# dmpac_targetdb register map
Vendor: Texas Instruments
Peripheral module from a debugger description file (folder hts_dmpac).
Registers are 32-bit, read-write, no defined reset value unless marked. A register's access mark holds for its fields unless they carry their own. Offsets are as the file gives them; lines under a group give offsets from that group; [hi:lo] are bit positions; {n}, {i} and the like mark numbered series; 'fields as' and 'values as' point back to an identical list; <NAME> marks a mode.

## DMPAC (part 1 of 5) — Depth and Motion Perception Accelerator (DMPAC)
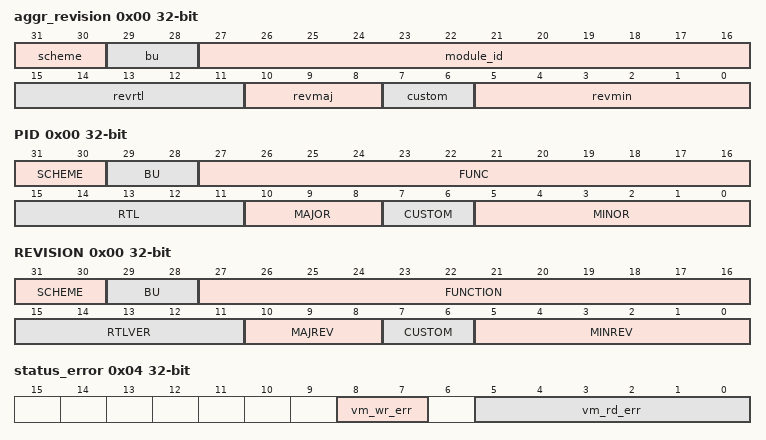
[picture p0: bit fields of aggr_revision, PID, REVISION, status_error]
0x00 aggr_revision ro — Revision parameters
  [31:30] scheme
  [29:28] bu
  [27:16] module_id
  [15:11] revrtl — RTL version
  [10:8] revmaj — Major version
  [7:6] custom — Custom version
  [5:0] revmin — Minor version
0x00 PID ro — DMPAC PID
  [31:30] SCHEME — Used to distinguish between old scheme and new scheme. Spare bit to encode future schemes
  [29:28] BU — BU indicatorDSPS ==> 0x0 WTBU ==> 0x1 Processors ==> 0x2
  [27:16] FUNC — Function indicates a software compatible module family. If there is no level of software compatibility a new FUNC number, and hence PID, should be assigned.
  [15:11] RTL — RTL Version. R as described in PDR with additional clarifications and definitions below. Must be easily ECO-able or controlled during fabrication. Ideally through a top level metal mask or e-fuse. This number is maintained/owned by IP design owner. RTL follows a numbering such as X.Y.R.Z which are explained in this table. R changes ONLY when: (1) PDS uploads occur which may have been due to spec changes (2) Bug fixes occur (3) Resets to '0' when X or Y changes. Design team has an internal 'Z' (customer invisible) number which increments on every drop that happens due to DV and RTL updates. Z resets to 0 when R increments.
  [10:8] MAJOR — Major Revision. X as described in PDR with additional clarifications/definitions below. This number is owned/maintained by IP specification owner. X is part of IP numbering X.Y.R.Z.X changes ONLY when: (1) There is a major feature addition. An example would be adding Master Mode to Utopia Level2. The Func field (or Class/Type in old PID format) will remain the same. X does NOT change due to: (1) Bug fixes (2) Change in feature parameters.
  [7:6] CUSTOM — Indicates a special version for a particular device. Consequence of use may avoid use of standard Chip Support Library (CSL) / Drivers. 0 if non-custom.
  [5:0] MINOR — Minor Revision. Y as described in PDR with additional clarifications/definitions below. This number is owned/maintained by IP specification owner. Y changes ONLY when: (1) Features are scaled (up or down). Flexibility exists in that this feature scalability may either be represented in the Y change or a specific register in the IP that indicates which features are exactly available. (2) When feature creeps from Is-Not list to Is list. But this may not be the case once it sees silicon - in which case X will change. Y does NOT change due to: (1) Bug fixes (2) Typos or clarifications (3) major functional/feature change/addition/deletion. Instead these changes may be reflected via R, S, X as applicable. Spec owner maintains a customer-invisible number 'S' which changes due to: (1) Typos/clarifications (2) Bug documentation. Note that this bug is not due to a spec change but due to implementation. Nevertheless, the spec tracks the IP bugs. An RTL release (say for silicon PG1.1) that occurs due to bug fix should document the corresponding spec number (X.Y.S) in its release notes.
0x00 REVISION ro
  [31:30] SCHEME
  [29:28] BU
  [27:16] FUNCTION — Module ID
  [15:11] RTLVER — RTL revisions
  [10:8] MAJREV — Major revision
  [7:6] CUSTOM — Custom revision
  [5:0] MINREV — Minor revision
{0x0+4i} pipeline_control_{i} (i=0..6) — Enable pipeline to activate all connected scheduler
  [0] pipe_en — Pipeline {i} enable, writing '1' activate pipeline , writing '0' during active pipeline is illegal and behavior is undefined, read '1' -> pipeline is active , read '0' -> pipeline is inactive
0x00 CTSETID ro — CTSET identification register
  [16:12] FUNCTION — Function : Indicates a Debug IP (0x2nn) and 0x80 is the identifier for CT-SET
  [11:5] RTL_VERSION — This field changes on bug fix, and resets to '0' when either Minor Revision or Major Revision field changes
  [8:3] MAJOR_REV — Major Revision. This field changes when there is a major feature change.
  [6:2] CUSTOM — Indicates a special version for a particular device. 0 if non-custom
  [28:2] BU — The value 10b designates this as Processor Business Unit IP
  [30:2] SCHEME — Used to distinguish between old Scheme and current
  [6:0] MINOR_REV — Minor Revision. This field changes when features are scaled up or down
0x00 status_param ro — The STATUS_PARAM register returns the LSE compile configuration parameters.
  [12:5] CORE_DW — Core Input Data Bus Width
  [23:5] CORE_OUT_DW — Core Output Channel Data Width
  [6:4] SL2_OUT_CH — Number of SL2 Output Channels
  [3] SL2_IN_CH_THR — Number of Input Channels per thread
  [17:3] PIX_MX_HT — Core_Input Pixel Matrix Height
  [10:2] SL2_OUT_H3A_CH — Number of SL2 H3A Output Channels
  [30:2] BYPASS_CH — Number of available input channel selection for loopback mode
  [2:1] VPORT_THR — Number of VPORT input enabled
  [20:1] HV_INSERT — H/VBLANK Insertion Supported (if 1)
  [21:1] BIT_AOFFSET — Source nibble offset address Supported (if 1)
  [22:1] LINE_SKIP_EN — Source Line Inc by 2 Supported (if 1)
  [28:1] CORE_OUT_2D — 1D or 2D output addressing mode(2D if 1)
  [29:1] OUT_SKIP_EN — Output Auto-Skip Enable
  [2:0] NTHR — Number of threads supported
0x00 status_param ro — The STATUS_PARAM register returns the LSE compile configuration parameters.
  fields as status_param
0x00 PID ro — DOF PID
  [16:12] FUNC — Function indicates a software compatible module family. If there is no level of software compatibility a new FUNC number, and hence PID, should be assigned.
  [11:5] RTL — RTL Version. R as described in PDR with additional clarifications and definitions below. Must be easily ECO-able or controlled during fabrication. Ideally through a top level metal mask or e-fuse. This number is maintained/owned by IP design owner. RTL follows a numbering such as X.Y.R.Z which are explained in this table. R changes ONLY when: (1) PDS uploads occur which may have been due to spec changes (2) Bug fixes occur (3) Resets to '0' when X or Y changes. Design team has an internal 'Z' (customer invisible) number which increments on every drop that happens due to DV and RTL updates. Z resets to 0 when R increments.
  [8:3] MAJOR — Major Revision. X as described in PDR with additional clarifications/definitions below. This number is owned/maintained by IP specification owner. X is part of IP numbering X.Y.R.Z.X changes ONLY when: (1) There is a major feature addition. An example would be adding Master Mode to Utopia Level2. The Func field (or Class/Type in old PID format) will remain the same. X does NOT change due to: (1) Bug fixes (2) Change in feature parameters.
  [6:2] CUSTOM — Indicates a special version for a particular device. Consequence of use may avoid use of standard Chip Support Library (CSL) / Drivers. 0 if non-custom.
  [28:2] BU — BU indicatorDSPS ==> 0x0 WTBU ==> 0x1 Processors ==> 0x2
  [30:2] SCHEME — Used to distinguish between old scheme and new scheme. Spare bit to encode future schemes
  [6:0] MINOR — Minor Revision. Y as described in PDR with additional clarifications/definitions below. This number is owned/maintained by IP specification owner. Y changes ONLY when: (1) Features are scaled (up or down). Flexibility exists in that this feature scalability may either be represented in the Y change or a specific register in the IP that indicates which features are exactly available. (2) When feature creeps from Is-Not list to Is list. But this may not be the case once it sees silicon - in which case X will change. Y does NOT change due to: (1) Bug fixes (2) Typos or clarifications (3) major functional/feature change/addition/deletion. Instead these changes may be reflected via R, S, X as applicable. Spec owner maintains a customer-invisible number 'S' which changes due to: (1) Typos/clarifications (2) Bug documentation. Note that this bug is not due to a spec change but due to implementation. Nevertheless, the spec tracks the IP bugs. An RTL release (say for silicon PG1.1) that occurs due to bug fix should document the corresponding spec number (X.Y.S) in its release notes.
0x00 PSE_MEM_RAM ro — pse_mem_ram diagnostic read only port, vbusp will stall until RAM is available for read
  [32:0] data — Data read from RAM. RAM is wider than 32bit vbus. MMR reads are byte addresses into RAM where RAM Width is extended/zero padded to next pwr2.
0x00 PID ro — SDE PID
  [16:12] FUNC — Function indicates a software compatible module family. If there is no level of software compatibility a new FUNC number, and hence PID, should be assigned.
  [11:5] RTL — RTL Version. R as described in PDR with additional clarifications and definitions below. Must be easily ECO-able or controlled during fabrication. Ideally through a top level metal mask or e-fuse. This number is maintained/owned by IP design owner. RTL follows a numbering such as X.Y.R.Z which are explained in this table. R changes ONLY when: (1) PDS uploads occur which may have been due to spec changes (2) Bug fixes occur (3) Resets to '0' when X or Y changes. Design team has an internal 'Z' (customer invisible) number which increments on every drop that happens due to DV and RTL updates. Z resets to 0 when R increments.
  [8:3] MAJOR — Major Revision. X as described in PDR with additional clarifications/definitions below. This number is owned/maintained by IP specification owner. X is part of IP numbering X.Y.R.Z.X changes ONLY when: (1) There is a major feature addition. An example would be adding Master Mode to Utopia Level2. The Func field (or Class/Type in old PID format) will remain the same. X does NOT change due to: (1) Bug fixes (2) Change in feature parameters.
  [6:2] CUSTOM — Indicates a special version for a particular device. Consequence of use may avoid use of standard Chip Support Library (CSL) / Drivers. 0 if non-custom.
  [28:2] BU — BU indicatorDSPS ==> 0x0 WTBU ==> 0x1 Processors ==> 0x2
  [30:2] SCHEME — Used to distinguish between old scheme and new scheme. Spare bit to encode future schemes
  [6:0] MINOR — Minor Revision. Y as described in PDR with additional clarifications/definitions below. This number is owned/maintained by IP specification owner. Y changes ONLY when: (1) Features are scaled (up or down). Flexibility exists in that this feature scalability may either be represented in the Y change or a specific register in the IP that indicates which features are exactly available. (2) When feature creeps from Is-Not list to Is list. But this may not be the case once it sees silicon - in which case X will change. Y does NOT change due to: (1) Bug fixes (2) Typos or clarifications (3) major functional/feature change/addition/deletion. Instead these changes may be reflected via R, S, X as applicable. Spec owner maintains a customer-invisible number 'S' which changes due to: (1) Typos/clarifications (2) Bug documentation. Note that this bug is not due to a spec change but due to implementation. Nevertheless, the spec tracks the IP bugs. An RTL release (say for silicon PG1.1) that occurs due to bug fix should document the corresponding spec number (X.Y.S) in its release notes.
0x00 CS_HIST_RAM ro — cs_hist_ram diagnostic read only port, vbusp will stall until RAM is available for read
  [21:11] rsvd — Always read as 0. Writes have no effect.
  [21:0] data — Data read from RAM
0x00 dru_pid ro — Peripheral ID Register
  [32:0] revision — PID Revision
0x00 dru_shared_evt_set access per field — DRU Shared Event Set Register
  [1:0] prot_err wo — Set the Prot Error event
0x00 cfg access per field — Configuration Register for Queue 0
  [16:8] consecutive_trans rw — This is the number of consecutive transactions that will be sent before allowing another queue of equal level to arbitrate to send commands. This is the maximum number of commands that it can send. If the queue has any delays such as virtual address lookup then the arbitration will be forced regardless of the number of commands.
  [24:8] rearb_wait rw — This is the number of commands that will be sent by other queues before allowing the queue to arbitrate again for the right to send commands. This is only started when a queue exhausted its consecutive trans count.
  [4] orderid rw — This configures the orderid for QUEUE0.
  [8:3] qos rw — This configures the QOS for QUEUE0. This should only be set for fixed priority queues and the lower queue should have the lower QoS.
  [3:0] pri rw — This configures the priority for QUEUE0. This will be the priority that will be presented on the External bus for all commands from this queue.
0x00 pid ro — The Revision Register contains the major and minor revisions for the module.
  [16:12] func — Module ID
  [11:5] rtl — RTL revision. Will vary depending on release.
  [8:3] major — Major revision
  [6:2] custom
  [28:2] bu — Business Unit: 10 = Processors
  [30:2] scheme — PID register scheme
  [6:0] minor — Minor revision
0x00 ecc_aggr_cfg_fw_region_0_control — The FW Region 0 Control Register defines the control fields for the slave ksdw_ecc_aggr.cfg region 0 firewall.
  [4:1] lock — Lock region. Once set region values cannot be modified.
  [8:1] background — Background enable for region. There can be 1 backgroun region per FW and foreground regions can have overlapping addresses only with the background region.
  [9:1] cache_mode — Cache mode for region. Set to 1 to check cache permissions. Set to 0 to ignore cache permissions.
  [4:0] enable — Enable region. A value of 0xA enables, others disable.
0x00 pid ro — The Revision Register contains the major and minor revisions for the module.
  fields as pid
{0x0+0x400*i} msram{i}_fw_region_0_control (i=0..3) — The FW Region 0 Control Register defines the control fields for the slave ksbus_msram{i}.slv region 0 firewall.
  fields as ecc_aggr_cfg_fw_region_0_control
0x04 status_error — The STATUS_ERROR register returns the LSE error status.
  [8:7] vm_wr_err — VBUSM I/F Last Write Error Status [14:11] Write Channel Number [10:8] VBUSM write error status
  [5:0] vm_rd_err — VBUSM I/F Last Read Error Status [4:3] Read Channel Number [2:0] VBUSM read error status
0x04 status_error — The STATUS_ERROR register returns the LSE error status.
  fields as status_error
0x04 dofcr access per field — Controls DOF operations
  [1] pyc_en_cfg rw — Pyramidal Top Co-located Predictor Enable bit. Set to 0x1 to enable use of pyramidal top colocated predictor during DOF processing.
  [2:1] pyl_en_cfg rw — Pyramidal Top Left Predictor Enable bit. Set to 0x1 to enable use of pyramidal top left predictor during DOF processing.
  [3:1] tp_en_cfg rw — Temporal Predictor Enable bit. Set to 0x1 to enable use of temporal predictor during the DOF processing.
  [4:1] dl_en_cfg rw — Delayed Left Predictor Enable bit. Set to 0x1 to enable use of delayed left predictor during the DOF processing.
  [16:1] lk_cs_en_cfg rw — LK refinement and confidence score generation enable bit. Set to 0x1 to enable LK and CS processing.
  [17:1] mf_en_cfg rw — Median filter enable bit. Set to 0x1 to enable median filter processing.
  [18:1] sofsparseen_cfg rw — sparse optical flow enable bit. Set to 0x1 to enable sparse optical flow processing.
  [24:1] cur_ct_type_cfg rw — Census transform type for current image.0: 24 bits generated for census transform by using a 5x5 neighborhood around the pixel.1: 32 bits generated for census transform by using a 7x7 neighborhood around the pixel where only 8 pixels are used from the periphery.
  [25:1] ref_ct_type_cfg rw — Census transform type for reference image.0: 24 bits generated for census transform by using a 5x5 neighborhood around the pixel.1: 32 bits generated for census transform by using a 7x7 neighborhood around the pixel where only 8 pixels are used from the periphery.
  [1:0] dof_en_cfg rw — DOF Enable. Set to 0x1 to enable DOF engine.
0x04 CTRL_REG access per field — SDE control register contains fields that can be used to control DMPAC operation.
  [28:4] rsvd ro — always read as 0. Write has no effect
  [1] sdeen rw — SDE enable. Write a '1' to enable DMPAC stereo
  [2:1] medfen rw — Median filter enable. Write a '1' to enable median filter for post processing
  [3:1] rrsrchen rw — Enable reduced range search on pixels near right margin where the search range is less than the configured maximum disparity. Write a '1' to enable reduced range search. Default is full range search where disparity is only produced for pixels where a full range search is possible
  [1:0] rsvd1 ro — always read as 0. Write has no effect
0x04 destination_id — The Destination ID Register defines the destination ID value for error messages.
  [8:0] dest_id — The destination ID.
{0x4+4i} ecc_aggr_cfg_fw_region_0_permission_{i} (i=0..2) — The FW Region 0 Permission {i} Register defines the permissions for the slave ksdw_ecc_aggr.cfg region 0 firewall.
  [16:8] priv_id — Allowed privid.
  [1] sec_supv_read — Secure supervisor read allowed.
  [2:1] sec_supv_cacheable — Secure supervisor cacheable allowed.
  [3:1] sec_supv_debug — Secure supervisor debug allowed.
  [4:1] sec_user_write — Secure user write allowed.
  [5:1] sec_user_read — Secure user read allowed.
  [6:1] sec_user_cacheable — Secure user cacheable allowed.
  [7:1] sec_user_debug — Secure user debug allowed.
  [8:1] nonsec_supv_write — Non-secure supervisor write allowed.
  [9:1] nonsec_supv_read — Non-secure supervisor read allowed.
  [10:1] nonsec_supv_cacheable — Non-secure supervisor cacheable allowed.
  [11:1] nonsec_supv_debug — Non-secure supervisor debug allowed.
  [12:1] nonsec_user_write — Non-secure user write allowed.
  [13:1] nonsec_user_read — Non-secure user read allowed.
  [14:1] nonsec_user_cacheable — Non-secure user cacheable allowed.
  [15:1] nonsec_user_debug — Non-secure user debug allowed.
  [1:0] sec_supv_write — Secure supervisor write allowed.
0x04 destination_id — The Destination ID Register defines the destination ID value for error messages.
  [8:0] dest_id — The destination ID.
{0x4+0x400*i} msram{i}_fw_region_0_permission_0 (i=0..3) — The FW Region 0 Permission 0 Register defines the permissions for the slave ksbus_msram{i}.slv region 0 firewall.
  fields as ecc_aggr_cfg_fw_region_0_permission_0
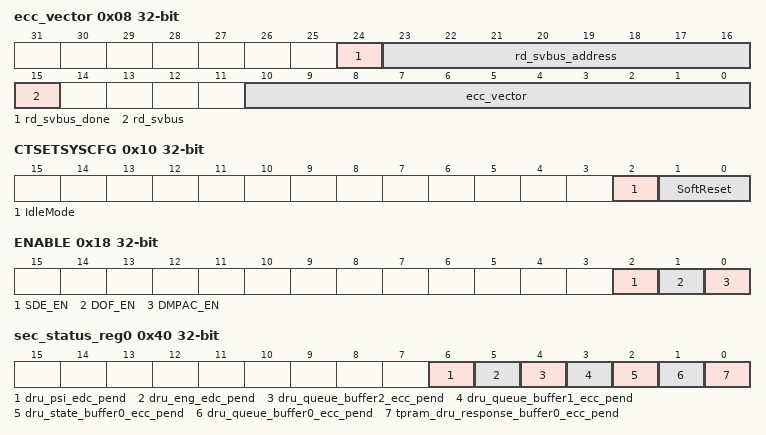
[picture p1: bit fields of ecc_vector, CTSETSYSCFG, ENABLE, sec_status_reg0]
0x08 ecc_vector
  [24] rd_svbus_done — Status to indicate if read on serial VBUS is complete, write of any value will clear this bit.
  [23:16] rd_svbus_address — Read address
  [15] rd_svbus — Write 1 to trigger a read on the serial VBUS
  [10:0] ecc_vector — Value written to select the corresponding ECC RAM for control or status
0x08 status_idle_mode ro — The STATUS_IDLE_MODE register returns IDLE status of LSE VBUSM port and in/output channels - 0: IDLE 1: ACTIVE
  [4] lse_in_chan — Input Channel[3:0] Status
  [12:4] lse_out_chan — Output Channel[3:0] Status
  [1] vm_wr_port — SL2 vbusm I/F Write Port Status
  [1:0] vm_rd_port — SL2 vbusm I/F Read Port Status
0x08 status_idle_mode ro — The STATUS_IDLE_MODE register returns IDLE status of LSE VBUSM port and in/output channels - 0: IDLE 1: ACTIVE
  fields as status_idle_mode
0x08 dofstat ro — Provides status info
  [10] curpaxaddrx_sts — Current Paxel Address X co-ordinate. Provides address of 2x2 paxel currently being processed.
  [9:1] curpaxaddry_sts — Current Paxel Address Y co-ordinate. Provides address of 2x2 paxel currently being processed.
  [1:0] dofact_sts — DOF Active Status. When read as 0x1, indicates DOF engine is in active state processing flow vector for the frame.
0x08 STATUS_REG ro — SDE status register contains fields that return the DMPAC stereo internal status.
  [21:11] rsvd — always read as 0. Write has no effect
  [2] medfcgstat — Median filter sub-module status: 2'b00: IDLE, 2'b01: ACTIVE, 2'b10: PAUSE, 2'b11: RSVD
  [4:2] drcgstat — DRCG sub-module status: 2'b00: IDLE, 2'b01: ACTIVE, 2'b10: PAUSE, 2'b11: RSVD
  [6:2] scastat — SCA sub-module status: 2'b00: IDLE, 2'b01: ACTIVE, 2'b10: PAUSE, 2'b11: RSVD
  [8:2] lccstat — LCC sub-module status: 2'b00: IDLE, 2'b01: ACTIVE, 2'b10: PAUSE, 2'b11: RSVD
  [10:1] sdeidle — sdeidle=1 indicate SDE is idle
  [2:0] dpackstat — Disparity packing sub-module status: 2'b00: IDLE, 2'b01: ACTIVE, 2'b10: PAUSE, 2'b11: RSVD
0x08 dru_capabilities ro — DRU Capabilities: Lists the capabilities of the channel for TR TYPE and formatting functions
  [20:12] rsvd_conf_spec — Reserved for Configuration Specific Features. This implementation has no configuration specific features.
  [35:4] eltype — Maximum element type value that is supported
  [39:4] dfmt — Maximum data reformatting function that is supported
  [43:4] sectr — Maximum second TR function that is supported
  [32:3] amode — The maximum AMODE that is supported. If AMODE is supported then DIR field must be supported for that AMODE.
  [1] type1 — Type 1 TR is supported
  [n:1] type{n} (n=2..15) — Type {n} TR is supported
  [16:1] trstatic — STATIC Field is supported
  [17:1] eol — EOL Field is supported
  [18:1] local_trig — Dedicated Local Trigger is supported
  [19:1] global_trig — Global Triggers 0 and 1 are supported
  [1:0] type0 — Type 0 TR is supported
{0x8+0x400*i} msram{i}_fw_region_0_permission_1 (i=0..3) — The FW Region 0 Permission 1 Register defines the permissions for the slave ksbus_msram{i}.slv region 0 firewall.
  fields as ecc_aggr_cfg_fw_region_0_permission_0
0x0C misc_status ro
  [10:0] num_rams — Indicates the number of RAMS serviced by the ECC aggregator
0x0C cfg_lse — The CFG_LSE register configures the LSE general hardware modes.
  [4:1] vm_arb_fixed_mode — VBUSM Arbitration Fixed Mode select 0: Round-Robin Arbitration (default) 1: Fixed-mode Arbitration
  [8:1] psa_en — Test mode Output Channel Signature Generation Enable 0: Disable (default) 1: EnableWhen enabled, LSE generates a unique CRC signature for each output channel's frame data at frame completion.
0x0C cfg_lse — The CFG_LSE register configures the LSE general hardware modes.
  fields as cfg_lse
0x0C IMGRES_REG access per field — SDE image resolution register contains fields that can be used to configure input image resolution.
  [23:9] rsvd ro — always read as 0. Write has no effect
  [16:7] iwinc rw — Image width increment factor. Image width iw=128 + 16*iwinc pixels, iwinc=0,1,...,120. Any value greater than 120 will be treated as 120.
  [10:6] rsvd1 ro — always read as 0. Write has no effect
  [6:0] ihinc rw — Image height increment factor. Image height ih=64 + 16*ihinc pixels, ihinc=0,1,...,60. Any value greater than 60 will be treated as 60.
{0xC+0x400*i} msram{i}_fw_region_0_permission_2 (i=0..3) — The FW Region 0 Permission 2 Register defines the permissions for the slave ksbus_msram{i}.slv region 0 firewall.
  fields as ecc_aggr_cfg_fw_region_0_permission_0
0x10 reserved_svbus — Reference other documents that contain the ECC RAM wrapper and EDC controller serial vbus register sets.
  [31:0] data — Serial VBUS register data
0x10 eoi_reg — End of Interrupt Register
  [7:0] eoi_vector — End of Interrupt Vector
0x10 CTSETSYSCFG access per field — CTSET system configuration register
  [2] IdleMode rw — Sets the Idle Mode for CTSET (0=Force Idle, 1=No Idle, 2=Smart Idle, 3= Smart Idle wakeup)
  [1:0] SoftReset rw — This will reset entire CTSET, except the registers and the CFG interface. This bit is automatically cleared by hardware. Reads always return 0
0x10 dofres access per field — Set up frame width, height
  [16:11] height_cfg rw — Height of frame (in pixel) to be processed by Optical Flow engine. 1024 pixel max and 16 pixels min. Refer to algorithm parameter section for restrictions.
  [12:0] width_cfg rw — Width of frame (in pixel) to be processed by Optical Flow engine. 2048 pixel max and 32 pixels min. Refer to algorithm parameter section for restrictions.
0x10 SRCHRNG_REG access per field — SDE search range register contains fields that can be used to configure disparity search range.
  [29:3] rsvd ro — always read as 0. Write has no effect
  [2:1] cfgdrange rw — Configure disparity search range in pixels. 2'b00: search range= 64 (-3 to 60 or 0 to 63), 2'b01:search range=128 (-3 to 124 or 0 to 127), others: search range =192 (-3 to 188 or 0 to 191).
  [1:0] cfgdmin rw — Configure minimum disparity (minDisp) to be searched in pixels. 0: minDisp=0, 1:minDisp= -3.
0x10 ecc_aggr_cfg_fw_region_0_start_address_l access per field — The FW Region 0 Start Address Low Register defines the start address bits 31 to 0 for the slave ksdw_ecc_aggr.cfg region 0 firewall.
  [20:12] start_address_l rw — Start address bits 31 to 12. Lowest 12 bits are forced to 0 as address must be 4KB aligned.
  [12:0] start_address_lsb ro — Start address bits 11 to 0 are forced to 0 as address must be 4KB aligned.
{0x10+0x400*i} msram{i}_fw_region_0_start_address_l access per field (i=0..3) — The FW Region 0 Start Address Low Register defines the start address bits 31 to 0 for the slave ksbus_msram{i}.slv region 0 firewall.
  fields as ecc_aggr_cfg_fw_region_0_start_address_l
0x14 intr_vector_reg ro — Interrupt Vector Register
  [31:0] intr_vector
0x14 SETSTR ro — CTSET status register
  [8:1] HWFIFOEmpty — System Event Trace FIFO status, 1 is empty, 0 means captured data not yet exported
  [1:0] ResetDone — Reset status, 0 means reset ongoing, 1 indicates completed
0x14 dofsr access per field — Setup horizontal and vertical search range.
  [16:6] vsr_p_cfg rw — Positive or Downward direction Vertical Search Range in pixels.
  [24:6] vsr_n_cfg rw — Negative or Upward direction Vertical Search Range in pixels.
  [8:0] hsr_cfg rw — Horizontal Search Range in pixels in both the directions.
0x14 LRCHCK_REG access per field — SDE left-right consistence check register contains fields that can be used to configure left-right consistence check.
  [24:8] rsvd ro — always read as 0. Write has no effect
  [8:0] diffthld rw — Left-right consistence check threshold in pixels. Program diffThld >= maxDisp-minDisp will disable Left-right consistence check.
0x14 ecc_aggr_cfg_fw_region_0_start_address_h — The FW Region 0 Start Address High Register defines the start address bits 47 to 32 for the slave ksdw_ecc_aggr.cfg region 0 firewall.
  [16:0] start_address_h — Start address bits 47 to 32.
{0x14+0x400*i} msram{i}_fw_region_0_start_address_h (i=0..3) — The FW Region 0 Start Address High Register defines the start address bits 47 to 32 for the slave ksbus_msram{i}.slv region 0 firewall.
  [16:0] start_address_h — Start address bits 47 to 32.
0x18 ENABLE access per field — DMPAC Enable
  [2] SDE_EN rw — Stereo Enable
  [1] DOF_EN rw — Optical Flow Enable
  [0] DMPAC_EN rw — DMPAC Enable
0x18 DBGTIMELOW ro — The 32 low order bits of the debug time value supplied on the time input interface
  [32:0] DBGTIME — debug time
0x18 sof access per field — Controls sparse optical flow output processing
  [12:0] max_output_count_per_line_cfg rw — Maximum number of MV output per line in case of sparse optical flow processing
0x18 TXTFLT_REG access per field — SDE texture based filtering control register contains fields that can be used to configure texture based filtering function.
  [23:9] rsvd ro — always read as 0. Write has no effect
  [8:1] txtthld rw — Scaled texture threshold. Any pixel whose texture metric is lower than txtthld is considered to be low texture. It is specified as normalized texture threshold times 1024. For instance, if txtthld = 204, the normalized texture threshold is 204/1024 = 0.1992.
  [1:0] txtflten rw — Enable texture based filtering
0x18 ecc_aggr_cfg_fw_region_0_end_address_l access per field — The FW Region 0 End Address Low Register defines the end address bits 31 to 0 to include for the slave ksdw_ecc_aggr.cfg region 0 firewall.
  [20:12] end_address_l rw — End address bits 31 to 12 to include in the match. Lowest 12 bits are forced to 1s as address must be 4KB aligned.
  [12:0] end_address_lsb ro — End address bits 11 to 0 are forced to 1s as address must be 4KB aligned minus 1.
{0x18+0x400*i} msram{i}_fw_region_0_end_address_l access per field (i=0..3) — The FW Region 0 End Address Low Register defines the end address bits 31 to 0 to include for the slave ksbus_msram{i}.slv region 0 firewall.
  fields as ecc_aggr_cfg_fw_region_0_end_address_l
0x1C CG_ENABLE_OVERRIDE access per field — Register to override the root clock gating done in DMPAC to reduce power.By default these bits are 0. it should be set to 1 only when we encounter some silicon bug.
  [0] cg_override rw — clock gating override
0x1C DBGTIMEHI ro — The 32 high order bits of the debug time value supplied on the time input interface
  [32:0] DBGTIME — debug time
0x1C PNLTY_REG access per field — SDE cost penalty configuration register contains fields that can be used to configure cost penalty function.
  [23:9] rsvd ro — always read as 0. Write has no effect
  [8:7] rsvd1 ro — always read as 0. Write has no effect
  [16:7] p1 rw — SDE aggregation penalty P1. Optimization penalty constant for small disparity change.
  [8:0] p2 rw — SDE aggregation penalty P2. Optimization penalty constant for large disparity change. p2 LTEQ 192. Any value greater than 192 will be treated as 192
0x1C ecc_aggr_cfg_fw_region_0_end_address_h — The FW Region 0 End Address High Register defines the end address bits 47 to 32 to include for the slave ksdw_ecc_aggr.cfg region 0 firewall.
  [16:0] end_address_h — End address bits 47 to 32 to include in the match.
{0x1C+0x400*i} msram{i}_fw_region_0_end_address_h (i=0..3) — The FW Region 0 End Address High Register defines the end address bits 47 to 32 to include for the slave ksbus_msram{i}.slv region 0 firewall.
  fields as ecc_aggr_cfg_fw_region_0_end_address_h
0x20 cfgwbase access per field — Current Frame GW Base address in SL2
  [20:0] addr_cfg rw — SL2 base byte address. Should be aligned to 64 bytes
0x20 CONFMAPG0_REG access per field — SDE confidence score mapping configuration register 0 specifies level 0 and 1 mapping threshold.
  [23:9] rsvd0 ro — always read as 0. Write has no effect
  [9:7] rsvd1 ro — always read as 0. Write has no effect
  [16:7] confmap_0 rw — SDE confidence score mapping 0. Internal confidence score will map to level 0 (of 8 level output) if it is less than confmap_0
  [7:0] confmap_1 rw — SDE confidence score mapping 1. Internal confidence score will map to level 1 if it is less than confmap_1 but greater than or equal to confmap_0
0x20 exception_logging_control — The Exception Logging Control Register controls the exception logging.
  [1] disable_pend — Disables logging pending when set.
  [1:0] disable_f — Disables logging when set.
0x20 exception_logging_control — The Exception Logging Control Register controls the exception logging.
  fields as exception_logging_control
{0x20+0x400*i} msram{i}_fw_region_1_control (i=0..3) — The FW Region 1 Control Register defines the control fields for the slave ksbus_msram{i}.slv region 1 firewall.
  fields as ecc_aggr_cfg_fw_region_0_control
0x24 CTSETCFG access per field — The 32 low order bits of the debug time value supplied on the time input interface The 32 high order bits of the debug time value supplied on the time input interface. Reading DBGTIMEHI latches the lower 32 bits of debug time value CTSET configuration register
  [28:4] Claim rw — Claim control and status. To program any bits other than 31 : 28, CTSET ownership must be claimed using bits 31 : 28.
  [1] StartCapt rw — Start capturing system events from external trigger detection
  [2:1] StopCapt rw — Stop capturing system events from external trigger detection
  [3:1] MsgMode rw — Message generated based on event detection, 0 is sampling window, 1 is event detection
  [4:1] EventLevel rw — 0 enables low level event detection, 1 enables high level event detection
  [7:1] SysEventCaptEn rw — When 1 the System event capture is enabled
0x24 cfgwwidth access per field — CFGW width, Max 2048 pix
  [13:0] width_cfg rw — Width of Frame Growing Window in bytes. Should be multiple of 64 bytes
0x24 CONFMAPG1_REG access per field — SDE confidence score mapping configuration register 1 specifies level 2 and 3 mapping threshold.
  [23:9] rsvd0 ro — always read as 0. Write has no effect
  [9:7] rsvd1 ro — always read as 0. Write has no effect
  [16:7] confmap_2 rw — SDE confidence score mapping 2. Internal confidence score will map to level 2 if it is less than confmap_2 but greater than or equal to confmap_1
  [7:0] confmap_3 rw — SDE confidence score mapping 3. Internal confidence score will map to level 3 if it is less than confmap_3 but greater than or equal to confmap_2
0x24 exception_logging_header0 ro — The Exception Logging Header 0 Register contains the first word of the header.
  [16:8] src_id — Source ID.
  [24:8] type_f — Type.
  [8:0] dest_id — Destination ID.
0x24 exception_logging_header0 ro — The Exception Logging Header 0 Register contains the first word of the header.
  fields as exception_logging_header0
{0x24+0x400*i} msram{i}_fw_region_1_permission_0 (i=0..3) — The FW Region 1 Permission 0 Register defines the permissions for the slave ksbus_msram{i}.slv region 1 firewall.
  fields as ecc_aggr_cfg_fw_region_0_permission_0
0x28 SETSPLREG access per field — System Event Sampling Window register
  [8:0] WindowSize rw — System events sampling window size expressed as CTSET cycles
0x28 cfgwheight access per field — CFGW Height, Max 32 rows
  [5:0] height_cfg rw — Height of Frame Growing Window. Max 31 rows.
0x28 CONFMAPG2_REG access per field — SDE confidence score mapping configuration register 2 specifies level 4 and 5 mapping threshold.
  [23:9] rsvd0 ro — always read as 0. Write has no effect
  [9:7] rsvd1 ro — always read as 0. Write has no effect
  [16:7] confmap_4 rw — SDE confidence score mapping 4. Internal confidence score will map to level 4 if it is less than confmap_4 but greater than or equal to confmap_3
  [7:0] confmap_5 rw — SDE confidence score mapping 5. Internal confidence score will map to level 5 if it is less than confmap_5 but greater than or equal to confmap_4
0x28 exception_logging_header1 ro — The Exception Logging Header 1 Register contains the second word of the header.
  [16:8] code, [24:8] group
0x28 exception_logging_header1 ro — The Exception Logging Header 1 Register contains the second word of the header.
  [16:8] code, [24:8] group
{0x28+0x400*i} msram{i}_fw_region_1_permission_1 (i=0..3) — The FW Region 1 Permission 1 Register defines the permissions for the slave ksbus_msram{i}.slv region 1 firewall.
  fields as ecc_aggr_cfg_fw_region_0_permission_0
0x2C CONFMAPG3_REG access per field — SDE confidence score mapping configuration register 3 specifies level 6 and 7 mapping threshold.
  [23:9] rsvd0 ro — always read as 0. Write has no effect
  [16:7] confmap_6 rw — SDE confidence score mapping 6. Internal confidence score will map to level 6 if it is less than confmap_6 but greater than or equal to confmap_5
  [16:0] rsvd1 ro — always read as 0. Write has no effect
0x2C exception_logging_data0 ro — The Exception Logging Data 0 Register contains the first word of the data.
  [32:0] addr_l — Address lower 32 bits.
0x2C exception_logging_data0 ro — The Exception Logging Data 0 Register contains the first word of the data.
  [32:0] addr_l — Address lower 32 bits.
{0x2C+0x400*i} msram{i}_fw_region_1_permission_2 (i=0..3) — The FW Region 1 Permission 2 Register defines the permissions for the slave ksbus_msram{i}.slv region 1 firewall.
  fields as ecc_aggr_cfg_fw_region_0_permission_0
0x30 SETEVTENBL1 — System event detection enable register 1
  [1] Event2DetEn — Event(2) Detection Enable
  [n-1:1] Event{n}DetEn (n=3..32) — Event({n}) Detection Enable
  [1:0] Event1DetEn — Event(1) Detection Enable
0x30 rfgwbase access per field — Reference Frame GW Base address in SL2
  fields as cfgwbase
0x30 BASEIMGADDR_REG access per field — SDE base image buffer start address register specifies the base image buffer start address in SL2.
  [20:12] rsvd ro — always read as 0. Write has no effect
  [20:0] basead rw — SL2 base image buffer start address (byte address aligned to 64 byte boundary, basead[5:0] should be programmed as 0).
0x30 exception_logging_data1 ro — The Exception Logging Data 1 Register contains the second word of the data.
  [16:0] addr_h — Address upper 16 bits.
0x30 exception_logging_data1 ro — The Exception Logging Data 1 Register contains the second word of the data.
  [16:0] addr_h — Address upper 16 bits.
{0x30+0x400*i} msram{i}_fw_region_1_start_address_l access per field (i=0..3) — The FW Region 1 Start Address Low Register defines the start address bits 31 to 0 for the slave ksbus_msram{i}.slv region 1 firewall.
  fields as ecc_aggr_cfg_fw_region_0_start_address_l
0x34 SETEVTENBL2 — System event detection enable register 2 (if number of events > 32)
  [1] Event34DetEn — Event(34) Detection Enable
  [n-33:1] Event{n}DetEn (n=35..64) — Event({n}) Detection Enable
  [1:0] Event33DetEn — Event(33) Detection Enable
0x34 rfgwwidth access per field — RFGW width, Max 2048 pix
  fields as cfgwwidth
0x34 BASEIMGWD_REG access per field — SDE base image buffer width register specifies the SL2 base image buffer width (The height is fixed at 24 for growing window).
  [20:12] rsvd ro — always read as 0. Write has no effect
  [12:0] bwidth rw — SL2 base image buffer width in bytes. bwidth has to satisfy bwidth >= 1.5iw (image width) and is aligned to 64 byte boundaries (LSB 6 bits are always programmed as 0).
0x34 exception_logging_data2 ro — The Exception Logging Data 2 Register contains the third word of the data.
  [16:12] routeid, [8:1] secure, [9:1] priv, [10:1] cacheable, [11:1] debug, [12:1] read, [13:1] write, [8:0] priv_id
0x34 exception_logging_data2 ro — The Exception Logging Data 2 Register contains the third word of the data.
  fields as exception_logging_data2
{0x34+0x400*i} msram{i}_fw_region_1_start_address_h (i=0..3) — The FW Region 1 Start Address High Register defines the start address bits 47 to 32 for the slave ksbus_msram{i}.slv region 1 firewall.
  [16:0] start_address_h — Start address bits 47 to 32.
0x38 SETEVTENBL3 — System event detection enable register 3 (if number of events > 64)
  [1] Event66DetEn — Event(66) Detection Enable
  [n-65:1] Event{n}DetEn (n=67..96) — Event({n}) Detection Enable
  [1:0] Event65DetEn — Event(65) Detection Enable
0x38 rfgwheight access per field — RFGW height, Max 256 rows
  [8:0] height_cfg rw — Height of Frame Growing Window. Max 255 rows.
0x38 REFIMGADDR_REG access per field — SDE reference image buffer start address register specifies the reference image buffer start address in SL2.
  [20:12] rsvd ro — always read as 0. Write has no effect
  [20:0] refad rw — SL2 reference image buffer start address (byte address aligned to 64 byte boundary, refad[5:0] should be programmed as 0).
0x38 exception_logging_data3 ro — The Exception Logging Data 3 Register contains the fourth word of the data.
  [10:0] bytecnt — Byte count.
0x38 exception_logging_data3 ro — The Exception Logging Data 3 Register contains the fourth word of the data.
  [10:0] bytecnt — Byte count.
{0x38+0x400*i} msram{i}_fw_region_1_end_address_l access per field (i=0..3) — The FW Region 1 End Address Low Register defines the end address bits 31 to 0 to include for the slave ksbus_msram{i}.slv region 1 firewall.
  fields as ecc_aggr_cfg_fw_region_0_end_address_l
0x3C sec_eoi_reg — EOI Register
  [0] eoi_wr
0x3C SETEVTENBL4 — System event detection enable register 4 (if number of events > 96)
  [1] Event98DetEn — Event(98) Detection Enable
  [n-97:1] Event{n}DetEn (n=99..128) — Event({n}) Detection Enable
  [1:0] Event97DetEn — Event(97) Detection Enable
0x3C REFIMGWD_REG access per field — SDE reference image buffer width register specifies the SL2 reference image buffer width (The height is fixed at 24 for growing window).
  [20:12] rsvd ro — always read as 0. Write has no effect
  [12:0] rwidth rw — SL2 reference image buffer width in bytes. rwidth has to satisfy rwidth >= 1.5*iw (image width) and is aligned to 64 byte boundaries (LSB 6 bits are always programmed as 0).
{0x3C+0x400*i} msram{i}_fw_region_1_end_address_h (i=0..3) — The FW Region 1 End Address High Register defines the end address bits 47 to 32 to include for the slave ksbus_msram{i}.slv region 1 firewall.
  fields as ecc_aggr_cfg_fw_region_0_end_address_h
0x40 sec_status_reg0 — Interrupt Status Register 0
  [6] dru_psi_edc_pend — Interrupt Pending Status for dru_psi_edc_pend
  [5] dru_eng_edc_pend — Interrupt Pending Status for dru_eng_edc_pend
  [4] dru_queue_buffer2_ecc_pend — Interrupt Pending Status for dru_queue_buffer2_ecc_pend
  [3] dru_queue_buffer1_ecc_pend — Interrupt Pending Status for dru_queue_buffer1_ecc_pend
  [2] dru_state_buffer0_ecc_pend — Interrupt Pending Status for dru_state_buffer0_ecc_pend
  [1] dru_queue_buffer0_ecc_pend — Interrupt Pending Status for dru_queue_buffer0_ecc_pend
  [0] tpram_dru_response_buffer0_ecc_pend — Interrupt Pending Status for tpram_dru_response_buffer0_ecc_pend
0x40 SETEVTENBL5 — System event detection enable register 5 (if number of events > 128)
  [1] Event130DetEn — Event(130) Detection Enable
  [n-129:1] Event{n}DetEn (n=131..145) — Event({n}) Detection Enable
  [17:1] Event1468DetEn — Event(146) Detection Enable
  [n-129:1] Event{n}DetEn (n=147..160) — Event({n}) Detection Enable
  [1:0] Event129DetEn — Event(129) Detection Enable
0x40 spbufbase access per field — Base address in SL2
  [24:3] depth_cfg rw — Depth of SL2 buffer
  [20:0] addr_cfg rw — SL2 base byte address. Should be aligned to 64 bytes
0x40 DISPBUFCFG_REG access per field — SDE disparity block buffer configuration register specifies the disparity output block buffer start address and number of buffers in SL2.
  [24:5] numdispbuf_m1 rw — number of SL2 disparity block buffers minus 1. For instance, programming numdispbuf_m1 to 1 makes a ping-pong buffer (number of disparity buffers is 2). When SL2 memory is available, programming numdispbuf_m1 to a larger value allow SDE to process more blocks before getting triggers for the corresponding blocks
  [20:4] rsvd1 ro — always read as 0. Write has no effect
  [29:3] rsvd0 ro — always read as 0. Write has no effect
  [20:0] dispbufad rw — SL2 disparity output block buffer start address (byte address aligned to 64 byte boundary, dispbufad[5:0] should be programmed as 0).
0x40 dru_comp_evt_set0 wo — DRU Completion Event Set Register
  [1] comp_evt1 — Set the Completion Event for channel 1
  [n:1] comp_evt{n} (n=2..31) — Set the Completion Event for channel {n}
  [1:0] comp_evt0 — Set the Completion Event for channel 0
0x40 status ro — Status Register for Queue 0
  [9] wr_total — This is the channel that the read half is currently working on.
  [18:9] rd_top — This is the channel that the read half is currently working on.
  [27:9] rd_total — This is the channel that the read half is currently working on.
  [9:0] wr_top — This is the channel that the write half is currently working on.
0x40 exception_pend_set — The Exception Logging Pending Set Register allows to set the pend signal.
  [1:0] pend_set — Write a 1 to set the exception pend signal.
0x40 exception_pend_set — The Exception Logging Pending Set Register allows to set the pend signal.
  [1:0] pend_set — Write a 1 to set the exception pend signal.
{0x40+0x400*i} msram{i}_fw_region_2_control (i=0..3) — The FW Region 2 Control Register defines the control fields for the slave ksbus_msram{i}.slv region 2 firewall.
  fields as ecc_aggr_cfg_fw_region_0_control
0x44 SETEVTENBL6 — System event detection enable register 6 (if number of events > 160)
  [1] Event162DetEn — Event(162) Detection Enable
  [n-161:1] Event{n}DetEn (n=163..192) — Event({n}) Detection Enable
  [1:0] Event161DetEn — Event(161) Detection Enable
0x44 tpbufbase access per field — Base address in SL2
  fields as spbufbase
0x44 IRCBUF_REG access per field — SDE image row cost buffer configuration register specifies the image row cost buffer start address in SL2.
  [20:12] rsvd1 ro — always read as 0. Write has no effect
  [20:0] ircbufad rw — SL2 image row cost buffer start address (byte address aligned to 64 byte boundary, ircbufad[5:0] should be programmed as 0).
